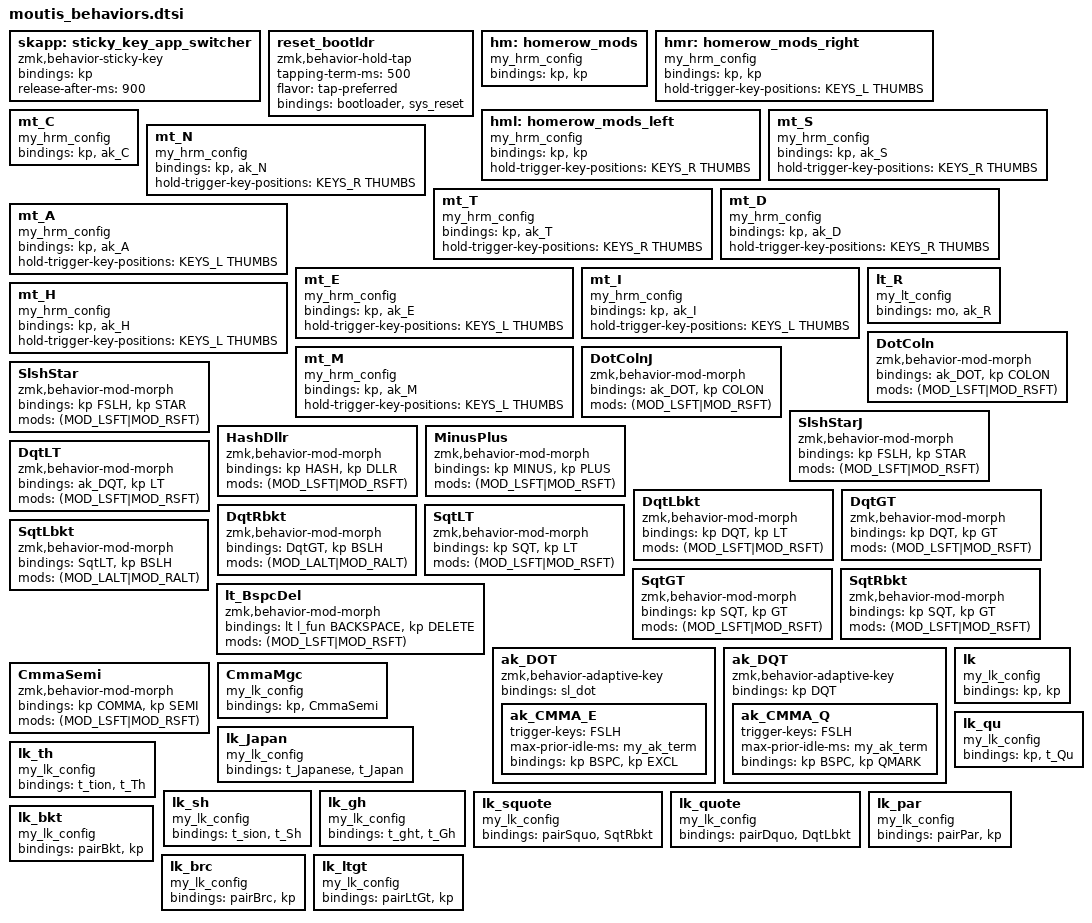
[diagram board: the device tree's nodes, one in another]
/*
 * moutis_behaviors.dtsi
 *
 * SPDX-License-Identifier: MIT
 *
 */


#define     my_hrm_config \
            compatible = "zmk,behavior-hold-tap"; \
            #binding-cells = <2>; \
            flavor = "balanced"; \
            hold-trigger-on-release; \
            tapping-term-ms = <my_tapping_term>; \
            quick-tap-ms = <my_quick_tapping_term>

#define     my_lt_config \
            compatible = "zmk,behavior-hold-tap"; \
            #binding-cells = <2>; \
            flavor = "tap-preferred"; \
            hold-trigger-on-release; \
            hold-while-undecided-linger; \
            tapping-term-ms = <my_tapping_term>; \
            quick-tap-ms = <my_quick_tapping_term>

#define     my_lk_config \
            compatible = "zmk,behavior-hold-tap"; \
            #binding-cells = <2>; \
            tapping-term-ms = <my_tapping_term>; \
            flavor = "tap-preferred"

        skapp: sticky_key_app_switcher {
            compatible = "zmk,behavior-sticky-key";
            #binding-cells = <1>;
            bindings = <&kp>;
            release-after-ms = <900>;
        };

#define rst_btld reset_bootldr 0 0 // simple macro to keep the keymap uncluttered
#define lkQuote lk_quote 0 0 // 包装宏：&lk_* 必须带 2 个参数，
                             // 补上两个 0 就能像普通键一样只占一格
#define lkSquote lk_squote 0 0 // 同上，给单引号位用
         reset_bootldr: reset_bootldr { // tap for reset, hold for bootloader
            compatible = "zmk,behavior-hold-tap";
            #binding-cells = <2>;
            tapping-term-ms = <500>;    // hold 0.5 seconds (Nice!Nano double-tap reset timing)
            flavor = "tap-preferred";
            bindings = <&bootloader>, <&sys_reset>;
        };

//
// home row mods
//

        hm: homerow_mods { // use on either hand
            my_hrm_config;
            bindings = <&kp>, <&kp>;
        };
        hmr: homerow_mods_right { // use on right hand to mod left
            my_hrm_config;
            bindings = <&kp>, <&kp>;
            hold-trigger-key-positions = <KEYS_L THUMBS>; // left hand allowed
        };
        hml: homerow_mods_left { // use on left hand to mod right
            my_hrm_config;
            bindings = <&kp>, <&kp>;
            hold-trigger-key-positions = <KEYS_R THUMBS>; // right hand allowed
        };
//
// these are really layout dependent, maybe should be separated? for now...
//
        mt_S: mt_S {
            my_hrm_config;
            bindings = <&kp>, <&ak_S>;
            hold-trigger-key-positions = <KEYS_R THUMBS>; // right hand allowed
        };
        mt_C: mt_C {  // C is on RIGHT hand in Pm, so it has no restriction
            my_hrm_config;
            bindings = <&kp>, <&ak_C>;
//            hold-trigger-key-positions = <KEYS_R THUMBS>; // right hand allowed
        };
        mt_N: mt_N {
            my_hrm_config;
            bindings = <&kp>, <&ak_N>;
            hold-trigger-key-positions = <KEYS_R THUMBS>; // right hand allowed
        };
        mt_T: mt_T {
            my_hrm_config;
            bindings = <&kp>, <&ak_T>;
            hold-trigger-key-positions = <KEYS_R THUMBS>; // right hand allowed
        };
        mt_D: mt_D {  // Onldy AU (Gold) has D on home
            my_hrm_config;
            bindings = <&kp>, <&ak_D>;
            hold-trigger-key-positions = <KEYS_R THUMBS>; // right hand allowed
        };
        mt_A: mt_A {
            my_hrm_config;
            bindings = <&kp>, <&ak_A>;
            hold-trigger-key-positions = <KEYS_L THUMBS>; // left hand allowed
       };
        mt_E: mt_E {
            my_hrm_config;
            bindings = <&kp>, <&ak_E>;
            hold-trigger-key-positions = <KEYS_L THUMBS>; // left hand allowed
        };
        mt_I: mt_I {
            my_hrm_config;
            bindings = <&kp>, <&ak_I>;
            hold-trigger-key-positions = <KEYS_L THUMBS>; // left hand allowed
        };
        mt_H: mt_H {
            my_hrm_config;
            bindings = <&kp>, <&ak_H>;
            hold-trigger-key-positions = <KEYS_L THUMBS>; // right hand allowed
        };
        mt_M: mt_M {        // M on right pinky in Rhodium
            my_hrm_config;
            bindings = <&kp>, <&ak_M>;
            hold-trigger-key-positions = <KEYS_L THUMBS>; // left hand allowed
        };
        lt_R: lt_R {
            my_lt_config;
            bindings = <&mo>, <&ak_R>;
        };


/*
 * modmorph behaviors
 * identified by the camel case of each of the keycodes
 */
        DotColn: DotColn {
            compatible = "zmk,behavior-mod-morph";
            #binding-cells = <0>;
            bindings = <&ak_DOT>, <&kp COLON>;
            mods = <(MOD_LSFT|MOD_RSFT)>;
        };
        DotColnJ: DotColnJ { // no adaptive Japanese
            compatible = "zmk,behavior-mod-morph";
            #binding-cells = <0>;
            bindings = <&ak_DOT>, <&kp COLON>;
            mods = <(MOD_LSFT|MOD_RSFT)>;
        };
        SlshStar: SlshStar {
            compatible = "zmk,behavior-mod-morph";
            #binding-cells = <0>;
            bindings = <&kp FSLH>, <&kp STAR>;
            mods = <(MOD_LSFT|MOD_RSFT)>;
        };
        SlshStarJ: SlshStarJ { // no adaptive Japanese
            compatible = "zmk,behavior-mod-morph";
            #binding-cells = <0>;
            bindings = <&kp FSLH>, <&kp STAR>;
            mods = <(MOD_LSFT|MOD_RSFT)>;
        };
        HashDllr: HashDllr {
            compatible = "zmk,behavior-mod-morph";
            #binding-cells = <0>;
            bindings = <&kp HASH>, <&kp DLLR>;
            mods = <(MOD_LSFT|MOD_RSFT)>;
        };
        MinusPlus: MinusPlus {
            compatible = "zmk,behavior-mod-morph";
            #binding-cells = <0>;
            bindings = <&kp MINUS>, <&kp PLUS>;
            mods = <(MOD_LSFT|MOD_RSFT)>;
        };

        DqtLT: DqtLT { // "<
            compatible = "zmk,behavior-mod-morph";
            #binding-cells = <0>;
            bindings = <&ak_DQT>, <&kp LT>;
            mods = <(MOD_LSFT|MOD_RSFT)>;
        };
        DqtLbkt: DqtLbkt { // 轻点 " / Shift <   （只两层，无 Alt）
            compatible = "zmk,behavior-mod-morph";
            #binding-cells = <0>;
            // 原本是 <&DqtLT>, <&kp BSLH> + Alt —— 三层（" / < / 反斜杠）。
            // 现在去掉 Alt 层，只留 " 和 <；成对输入改由外层 lk_quote 的长按负责。
            //
            // 内层必须用 &kp DQT，不能用 &DqtLT：
            //   DqtLT 内部调 &ak_DQT，而 DqtLbkt 现在被 hold-tap 当 tap 行为引用，
            //   经 DqtLT 会形成循环引用。直接发 &kp DQT 即可断开。
            //   代价：双引号位不再有“/ 后跟引号 -> ?”那条自适应规则。该规则触发键是
            //   FSLH，只在“先打了 /”时才需要，而 / 只在基础层有 —— 无实际损失。
            bindings = <&kp DQT>, <&kp LT>;
            mods = <(MOD_LSFT|MOD_RSFT)>;
        };
        DqtGT: DqtGT { // ">
            compatible = "zmk,behavior-mod-morph";
            #binding-cells = <0>;
            bindings = <&kp DQT>, <&kp GT>;
            mods = <(MOD_LSFT|MOD_RSFT)>;
        };
        DqtRbkt: DqtRbkt { // "]
            compatible = "zmk,behavior-mod-morph";
            #binding-cells = <0>;
            // 原为 <&kp LS(LA(BSLH))> = Mac 的 ⇧⌥\ → “]”。同上，改为 BSLH。
            bindings = <&DqtGT>, <&kp BSLH>;
            mods = <(MOD_LALT|MOD_RALT)>;
        };
        SqtLT: SqtLT { // '<
            compatible = "zmk,behavior-mod-morph";
            #binding-cells = <0>;
            bindings = <&kp SQT>, <&kp LT>;
            mods = <(MOD_LSFT|MOD_RSFT)>;
        };
        SqtLbkt: SqtLbkt { // '[
            compatible = "zmk,behavior-mod-morph";
            #binding-cells = <0>;
            // 原为 <&kp LA(BSLH)> = Mac 的 ⌥\ → “'”。同上，改为 BSLH。
            bindings = <&SqtLT>, <&kp BSLH>;
            mods = <(MOD_LALT|MOD_RALT)>;
        };
        SqtGT: SqtGT { // '>
            compatible = "zmk,behavior-mod-morph";
            #binding-cells = <0>;
            bindings = <&kp SQT>, <&kp GT>;
            mods = <(MOD_LSFT|MOD_RSFT)>;
        };
        SqtRbkt: SqtRbkt { // 轻点 ' / Shift >   （只两层，无 Alt）
            compatible = "zmk,behavior-mod-morph";
            #binding-cells = <0>;
            // 原本是 <&SqtGT>, <&kp BSLH> + Alt —— 三层（' / > / 反斜杠）。
            // 现在去掉 Alt 层，只留 ' 和 >；成对输入改由外层 lk_squote 的长按负责。
            bindings = <&kp SQT>, <&kp GT>;
            mods = <(MOD_LSFT|MOD_RSFT)>;
        };

        lt_BspcDel: lt_BspcDel { // layer-tap mod-morph
            compatible = "zmk,behavior-mod-morph";
            #binding-cells = <0>;
            bindings = <&lt l_fun BACKSPACE>, <&kp DELETE>;
            mods = <(MOD_LSFT|MOD_RSFT)>;
        };
        ak_DOT: ak_DOT {
            compatible = "zmk,behavior-adaptive-key";
            #binding-cells = <0>;
            bindings = <&sl_dot>;

            ak_CMMA_E { trigger-keys = <FSLH>; max-prior-idle-ms = <my_ak_term>; bindings = <&kp BSPC  &kp EXCL>; };
        };
        ak_DQT: ak_DQT {
            compatible = "zmk,behavior-adaptive-key";
            #binding-cells = <0>;
            bindings = <&kp DQT>;

            ak_CMMA_Q { trigger-keys = <FSLH>; max-prior-idle-ms = <my_ak_term>; bindings = <&kp BSPC  &kp QMARK>; };
        };

/* Comma Magic */
#define CommaMagic CmmaMgc CAPSLOCK 0   // simple macro to keep the keymap uncluttered

        CmmaSemi: CmmaSemi { // press = COMMA,shift = Semicolon
            compatible = "zmk,behavior-mod-morph";
            #binding-cells = <0>;
            bindings = <&kp COMMA>, <&kp SEMI>;
//            bindings = <&ak_CMMA>, <&kp SEMI>;
            mods = <(MOD_LSFT|MOD_RSFT)>;
        };
//        ak_CMMA: ak_CMMA { // double-tap comma = caps_word
//            compatible = "zmk,behavior-adaptive-key";
//            #binding-cells = <0>;
//            bindings = <&kp COMMA>;
//
//            ak_CMMA_cap { trigger-keys = <COMMA>; max-prior-idle-ms = <my_ak_term>; bindings = <&kp BSPC  &caps_word>; };
//        };
        CmmaMgc: CmmaMgc {              // Hold for CAPSLOCK, tap for COMMA
            my_lk_config;
            bindings = <&kp>, <&CmmaSemi>;
        };

/*
 * lk_ linger key behaviors (approximated via hold-tap)
 * most require a combo to execute the multiple key taps
 */
        lk: lk {    // a generic linger behavior
            my_lk_config;
            bindings = <&kp>, <&kp>;
        };

        lk_qu: lk_qu {
            my_lk_config;
            bindings = <&kp>, <&t_Qu>;
        };
        // ⚠️ 已删除 7 个 macOS 死键 linger 行为（lk_E_accent / lk_E_grave /
        //    lk_E_acute / lk_O_macron / lk_A_ring / lk_U_umlaut / lk_C_cedille）。
        //    它们依赖 Mac 的 Option 死键宏，Windows 上无法工作；
        //    对应的 diac* combo 已改为直接输出单个字母（见 moutis_combos.dtsi）。

        lk_Japan: lk_Japan { // Japan on tap, Japanese on "linger"
            my_lk_config;
            bindings = <&t_Japanese>, <&t_Japan>;
        };
        lk_th: lk_th { // Th on tap, tion on "linger"
            my_lk_config;
            bindings = <&t_tion>, <&t_Th>;
        };
        lk_sh: lk_sh { // Sh on tap, sion on "linger"
            my_lk_config;
            bindings = <&t_sion>, <&t_Sh>;
        };
        lk_gh: lk_gh { // Gh on tap, Ght on "linger"
            my_lk_config;
            bindings = <&t_ght>, <&t_Gh>;
        };
        // ── 引号位：轻点引号 / Shift 尖括号 / 长按成对 ──────────────────
        // hold-tap 的 cell 顺序是 <长按>, <轻点> —— 依据 ZMK 源码 behavior_hold_tap.c：
        //   bindings[0] -> hold_behavior_dev，bindings[1] -> tap_behavior_dev
        //   （对比 lk_th = <&t_tion>, <&t_Th>，注释写 "Th on tap, tion on linger"）。
        // 用的时候必须走上面的 lkQuote / lkSquote 包装宏
        // （&lk_* 声明的是 #binding-cells = <2>，得补两个参数）。
        lk_squote: lk_squote { // 单引号：轻点 ' / Shift > / 长按 ''
            my_lk_config;
            bindings = <&pairSquo>, <&SqtRbkt>;
        };
        lk_quote: lk_quote { // 双引号：轻点 " / Shift < / 长按 ""
            my_lk_config;                       // 保持 #binding-cells = <2>：
                                                // ZMK 的 hold-tap binding 硬性规定
                                                // 必须是 2，改成 0 会被 devicetree 拒绝
            bindings = <&pairDquo>, <&DqtLbkt>;
        };
        lk_par: lk_par { // ( on tap, () on "linger"
            my_lk_config;
            bindings = <&pairPar>, <&kp>;
        };
        lk_bkt: lk_bkt { // [ on tap, [] on "linger"
            my_lk_config;
            bindings = <&pairBkt>, <&kp>;
        };
        lk_brc: lk_brc {
            my_lk_config;
            bindings = <&pairBrc>, <&kp>;
        };
        lk_ltgt: lk_ltgt { // < on tap, <|> on "linger"
            my_lk_config;
            bindings = <&pairLtGt>, <&kp>;
        };
